# dm64lc_cslr_ddr2 register map
Vendor: Texas Instruments
Peripheral module from a debugger description file.
Registers are 32-bit, access not given, reset 0x0 unless marked. A register's access mark holds for its fields unless they carry their own. Offsets are as the file gives them; lines under a group give offsets from that group; [hi:lo] are bit positions; {n}, {i} and the like mark numbered series; 'fields as' and 'values as' point back to an identical list; <NAME> marks a mode.

## DDR2 — The DDR2 memory controller is used to interface with JESD79D-2A standard compliant DDR2 SDRAM devices.
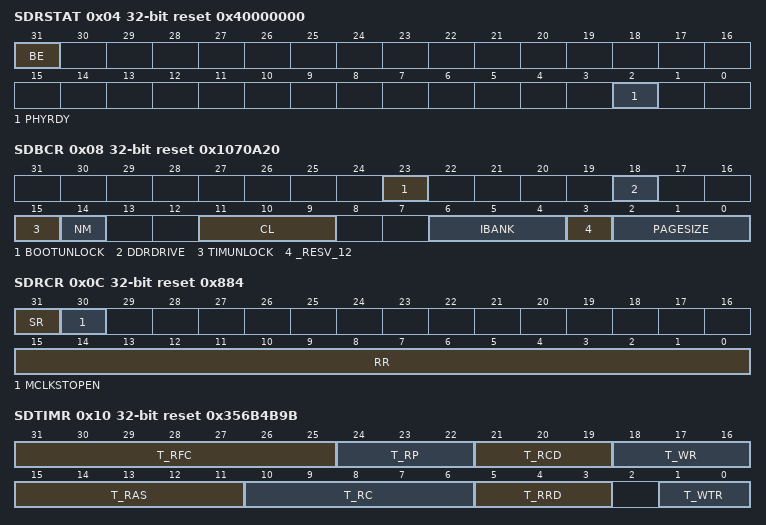
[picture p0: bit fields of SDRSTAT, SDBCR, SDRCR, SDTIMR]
0x04 SDRSTAT reset 0x40000000 — This register reflects the status
  [31] BE ro — Big Endian mode flag (indicating endianness selection). Reset value depends on device configuration.
  [2] PHYRDY ro — DDR2 memory controller DLL ready. Specifies whether the DDR2 memory controller DLL is powered up and locked.
    0=DEASSERTED (DLL is not ready, either powered down, in reset, or not locked.); 1=ASSERTED (DLL is powered up, locked, and ready for operation.)
0x08 SDBCR reset 0x1070A20 — This register is used to configure the SDRAM
  [23] BOOTUNLOCK rw — Boot unlock. Controls the write permission settings for the DDRDRIVE bit. To change the DDRDRIVE bit value use the following sequence: 1. Write a 1 to the BOOTUNLOCK bit. 2. Write a 0 to the BOOTUNLOCK bit along with the desired value of the DDRDRIVE bit.
  [18] DDRDRIVE rw — DDR2 SDRAM drive strength. Configures the output driver impedance control value of the DDR2 SDRAM memory. To change the DDRDRIVE bit value use the following sequence: 1. Write a 1 to the BOOTUNLOCK bit. 2. Write a 0 to the BOOTUNLOCK bit along with the desired value of the DDRDRIVE bit.
  [15] TIMUNLOCK rw — Timing unlock. Controls the write permission settings for the SDRAM Timing Register and SDRAM Timing Register 2.
    0=CLEAR (Register fields in the SDRAM timing register (SDTIMR) and the SDRAM timing register 2 (SDTIMR2) may not be changed.); 1=SET (Register fields in the SDRAM timing register (SDTIMR) and the SDRAM timing register 2 (SDTIMR2) may be changed.)
  [14] NM rw — DDR2 data bus width.
    0=32BIT (32-bit bus width.); 1=16BIT (16-bit bus width.)
  [11:9] CL rw — CAS Latency. The value of this field defines the CAS latency, to be used when accessing connected SDRAM devices. A write to this field will cause the EMIF to start the SDRAM initialization sequence. This field is writeable only when the timing_unlock bit is unlocked.
    2=TWO (CAS Latency = 2); 3=THREE (CAS Latency = 3); 4=FOUR (CAS Latency = 4); 5=FIVE (CAS Latency = 5)
  [6:4] IBANK rw — Internal DDR2 bank setup. Defines the number of internal banks on the external DDR2 memory.
    0=ONE (One bank); 1=TWO (Two banks); 2=FOUR (Four banks); 3=EIGHT (Eight banks)
  [3] _RESV_12 — Read Command FIFO depth for a particular configuration. (access N)
  [2:0] PAGESIZE rw — Page Size. Defines the internal page size of connected SDRAM devices.
0x0C SDRCR reset 0x884 — This register controls the SDRAM refreshing
  [31] SR rw — Selects self refresh mode
    0=DISABLE (DDR2 memory controller exits the self-refresh mode.); 1=ENABLE (DDR2 memory controller enters the self-refresh mode.)
  [30] MCLKSTOPEN rw — MCLK stop enable.
    0=DISABLE (Disables MCLK stopping, MCLK may not be stopped.); 1=ENABLE (Enables MCLK stopping, MCLK may be stopped. The SR bit must be set to 1 before setting the MCLKSTOPEN bit to 1.)
  [15:0] RR rw — Refresh rate. Defines the rate at which the attached DDR2 devices will be refreshed. The value of this field may be calculated with the following equation: RR=DDR2 frequency/DDR2 refresh rate
0x10 SDTIMR reset 0x356B4B9B — Holds the Timing parameters of SDRAM
  [31:25] T_RFC rw — Specifies the minimum number of DDR_CLKO cycles from a refresh or load mode command to a refresh or activate command, minus 1. Corresponds to the trfc AC timing parameter in the DDR2 data sheet. Calculate by: T_RFC = (trfc/DDR_CLKO) 1
  [24:22] T_RP rw — Specifies the minimum number of DDR_CLKO cycles from a precharge command to a refresh or activate command, minus 1. Corresponds to the trp AC timing parameter in the DDR2 data sheet. Calculate by: T_RP = (trp/DDR_CLKO) - 1
  [21:19] T_RCD rw — Specifies the minimum number of DDR_CLKO cycles from an activate command to a read or write command, minus 1. Corresponds to the trcd AC timing parameter in the DDR2 data sheet. Calculate by: T_RCD = (trcd/DDR_CLKO) - 1.
  [18:16] T_WR rw — Specifies the minimum number of DDR_CLKO cycles from the last write transfer to a precharge command, minus 1. Corresponds to the twr AC timing parameter in the DDR2 data sheet. Calculate by: T_WR = (twr/DDR_CLKO) - 1
  [15:11] T_RAS rw — Specifies the minimum number of DDR_CLKO cycles from an activate command to a precharge command, minus 1. Corresponds to the tras AC timing parameter in the DDR2 data sheet. Calculate by: T_RAS = (tras/DDR_CLKO) - 1
  [10:6] T_RC rw — Specifies the minimum number of DDR_CLKO cycles from an activate command to an activate command, minus 1. Corresponds to the trc AC timing parameter in the DDR2 data sheet. Calculate by: T_RC = (trc/DDR_CLKO) - 1
  [5:3] T_RRD rw — Specifies the minimum number of DDR_CLKO cycles from an activate command to an activate command in a different bank, minus 1. Corresponds to the trrd AC timing parameter in the DDR2 data sheet. Calculate by: T_RRD = (trrd/DDR_CLKO) - 1
  [1:0] T_WTR rw — Specifies the minimum number of DDR_CLKO cycles from the last write to a read command, minus 1. Corresponds to the twtr AC timing parameter in the DDR2 data sheet. Calculate by: T_WTR = (twtr/DDR_CLKO) - 1
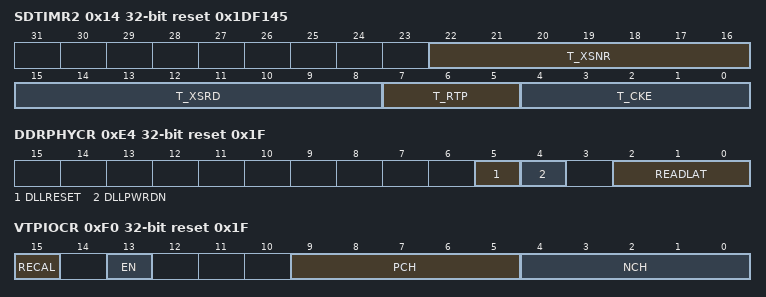
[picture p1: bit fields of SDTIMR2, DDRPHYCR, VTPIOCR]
0x14 SDTIMR2 reset 0x1DF145 — Holds the Timing parameters of SDRAM
  [22:16] T_XSNR rw — Specifies the minimum number of DDR_CLKO cycles from a self-refresh exit to any other command except a read command, minus 1. Corresponds to the txsnr AC timing parameter in the DDR2 data sheet. Calculate by: T_XSNR = (trtp/DDR_CLKO) - 1
  [15:8] T_XSRD rw — Specifies the minimum number of DDR_CLKO cycles from a self-refresh exit to a read command, minus 1. Corresponds to the txsrd AC timing parameter in the DDR2 data sheet. Calculate by: T_XSRD = txsrd - 1
  [7:5] T_RTP rw — Specifies the minimum number of DDR_CLKO cycles from a last read command to a precharge command, minus 1. Corresponds to the trtp AC timing parameter in the DDR2 data sheet. Calculate by: T_RTP = (trtp/DDR_CLKO) - 1
  [4:0] T_CKE rw — Specifies the minimum number of DDR_CLKO cycles between transitions on the DDR_CKE pin, minus 1. Corresponds to the tcke AC timing parameter in the DDR2 data sheet. Calculate by: T_CKE = tcke - 1
0x20 PBBPR reset 0xFF — Priority Raise Old Counter.
  [7:0] PR_OLD_COUNT rw — Priority raise old counter. Specifies the number of memory transfers after which the DDR2 memory controller will elevate the priority of the oldest command in the command FIFO.
0xC0 IRR — Flags the interrupts
  [2] LT rw — Line trap. Write a 1 to clear LT and the LTM bit in the interrupt masked register (IMR); a write of 0 has no effect.
    1=CLEAR
0xC4 IMR — Reflects the flags in IRR
  [2] LTM rw — Line trap masked. Write a 1 to clear LTM and the LT bit in the interrupt raw register (IRR); a write of 0 has no effect.
    1=CLEAR
0xC8 IMSR — Enables the corresponding interrupt
  [2] LTMSET rw — Line trap interrupt set. Write a 1 to set LTMSET and the LTMCLR bit in the interrupt mask clear register (IMCR); a write of 0 has no effect.
    1=SET
0xCC IMCR — Disables the corresponding interrupt
  [2] LTMCLR rw — Line trap interrupt clear. Write a 1 to clear LTMCLR and the LTMSET bit in the interrupt mask set register (IMSR); a write of 0 has no effect.
    1=CLEAR
0xE4 DDRPHYCR reset 0x1F — This register is used to control the DDR PHY.
  [5] DLLRESET rw — Reset DLL.
    0=OUTOFRESET (DLL is out of reset.); 1=RESET (Places the DLL in reset.)
  [4] DLLPWRDN rw — Power down DLL
    0=DISABLE (DLL is powered up.); 1=ENABLE (DLL is powered down, if DLLPWRDN and the SR bit and MCLKSTOPEN bit in the SDRAM refresh control register (SDRCR) are set to 1.)
  [2:0] READLAT rw — Read latency. Read latency is equal to CAS latency plus round trip board delay for data minus 1. The maximum value of read latency that is supported is CAS latency plus 3. The minimum read latency value that is supported is CAS latency plus 1. The read latency value is defined in number of MCLK/DDR_CLKO cycles.
0xF0 VTPIOCR reset 0x1F — This register is used to control the VTP IO
  [15] RECAL rw — Start VTP IO calibration.
    1=RECAL (Transition from 0 to 1 starts VTP IO calibration.)
  [13] EN rw — VTP enable.
    0=DISABLED (VTP IO calibration is disabled.); 1=ENABLED (VTP IO calibration is enabled.)
  [9:5] PCH rw — P channel value. This value is driven to the IO to calibrate the impedance of the IO. The value of PCH is determined by reading the DDR VTP register (DDRVTPR).
  [4:0] NCH rw — N channel value. This value is driven to the IO to calibrate the impedance of the IO. The value of NCH is determined by reading the DDR VTP register (DDRVTPR).
